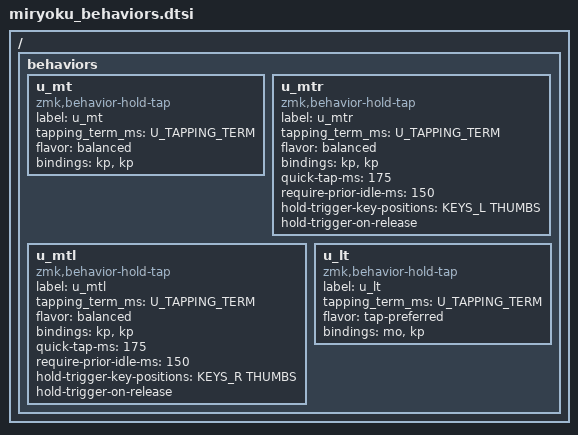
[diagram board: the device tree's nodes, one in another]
// Copyright 2022 Manna Harbour
// https://github.com/manna-harbour/miryoku
#define KEYS_L 4 3 2 1 0 14 13 12 11 10 25 24 23 22 21 20
#define KEYS_R 5 6 7 8 9 15 16 17 18 19 26 27 28 29 30 31
#define THUMBS 34 33 32 35 36 37

/ {
  behaviors {
    u_mt: u_mt {
      compatible = "zmk,behavior-hold-tap";
      label = "u_mt";
      #binding-cells = <2>;
      tapping_term_ms = <U_TAPPING_TERM>;
      flavor = "balanced";
      bindings = <&kp>, <&kp>;
    };
    u_mtr: u_mtr {
      compatible = "zmk,behavior-hold-tap";
      label = "u_mtr";
      #binding-cells = <2>;
      tapping_term_ms = <U_TAPPING_TERM>;
      flavor = "balanced";
      bindings = <&kp>, <&kp>;
      quick-tap-ms = <175>;
      require-prior-idle-ms = <150>;
      hold-trigger-key-positions = <KEYS_L THUMBS>;
      hold-trigger-on-release;
    };
    u_mtl: u_mtl {
      compatible = "zmk,behavior-hold-tap";
      label = "u_mtl";
      #binding-cells = <2>;
      tapping_term_ms = <U_TAPPING_TERM>;
      flavor = "balanced";
      bindings = <&kp>, <&kp>;
      quick-tap-ms = <175>;
      require-prior-idle-ms = <150>;
      hold-trigger-key-positions = <KEYS_R THUMBS>;
      hold-trigger-on-release;
    };
    u_lt: u_lt {
      compatible = "zmk,behavior-hold-tap";
      label = "u_lt";
      #binding-cells = <2>;
      tapping_term_ms = <U_TAPPING_TERM>;
      flavor = "tap-preferred";
      bindings = <&mo>, <&kp>;
    };
  };
};
